# STM32H743 register map
File version: 2.4
CPU: CM7 r0p1, little endian, MPU, FPU, 4 interrupt priority bits
Registers are 32-bit, read-write, reset 0x0 unless marked. A register's access mark holds for its fields unless they carry their own. Offsets are from the block's base; [hi:lo] are bit positions; {n}, {i} and the like mark numbered series; 'fields as' and 'values as' point back to an identical list.

## RCC — 复位与时钟控制
Base 0x58024400
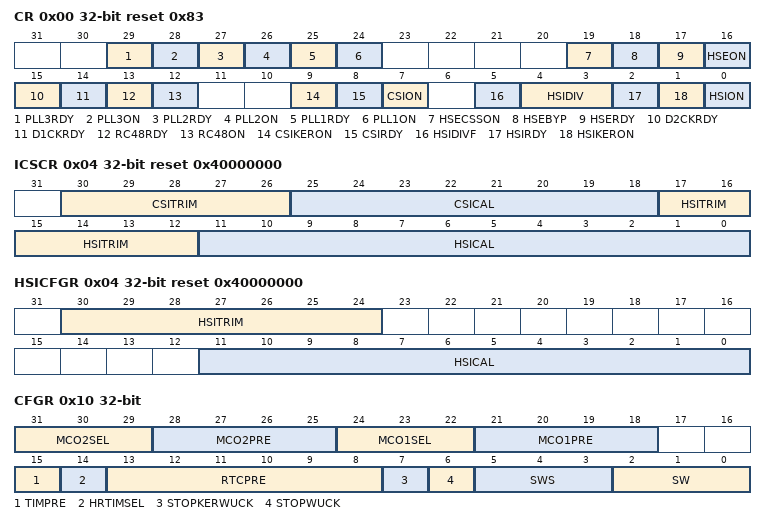
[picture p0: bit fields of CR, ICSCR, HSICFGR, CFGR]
0x00 CR reset 0x83 — 时钟控制寄存器
  [29] PLL3RDY — PLL3 时钟就绪标志位
  [28] PLL3ON — PLL3 使能
  [27] PLL2RDY — PLL2 时钟就绪标志位
  [26] PLL2ON — PLL2 使能
  [25] PLL1RDY — PLL1 时钟就绪标志位
  [24] PLL1ON — PLL1 使能
  [19] HSECSSON — HSE 时钟安全系统使能
  [18] HSEBYP — HSE 时钟旁路
  [17] HSERDY — HSE 时钟就绪标志位
  [16] HSEON — HSE 时钟使能
  [15] D2CKRDY — D2 域时钟就绪标志位
  [14] D1CKRDY — D1 域时钟就绪标志位
  [13] RC48RDY — RC48 时钟就绪标志位
  [12] RC48ON — RC48 时钟使能
  [9] CSIKERON — CSI 时钟停止模式下使能
  [8] CSIRDY — CSI 时钟就绪标志位
  [7] CSION — CSI 时钟使能
  [5] HSIDIVF — HSI 分频器标志位
  [4:3] HSIDIV — HSI 时钟分频器
  [2] HSIRDY — HSI 时钟就绪标志位
  [1] HSIKERON — 高速内部时钟停止模式下使能
  [0] HSION — 内部高速时钟使能
0x04 ICSCR access per field reset 0x40000000 — RCC 内部时钟源校准寄存器
  [30:26] CSITRIM rw — CSI 时钟微调
  [25:18] CSICAL ro — CSI 时钟校准值
  [17:12] HSITRIM rw — HSI 时钟微调
  [11:0] HSICAL ro — HSI 时钟校准值
0x04 HSICFGR access per field reset 0x40000000 (alternate view of ICSCR) — RCC HSI 配置寄存器
  [30:24] HSITRIM rw — HSI 时钟微调
  [11:0] HSICAL ro — HSI 时钟校准值
0x08 CRRCR ro — RCC 时钟恢复 RC 寄存器
  [9:0] RC48CAL — 内部 RC 48 MHz 时钟校准值
0x10 CFGR — RCC 时钟配置寄存器
  [31:29] MCO2SEL — 微控制器时钟输出 2
  [28:25] MCO2PRE — MCO2 预分频器
  [24:22] MCO1SEL — 微控制器时钟输出 1
  [21:18] MCO1PRE — MCO1 预分频器
  [15] TIMPRE — 定时器时钟预分频器选择
  [14] HRTIMSEL — 高分辨率定时器时钟预分频器选择
  [13:8] RTCPRE — RTC 时钟的 HSE 分频因子
  [7] STOPKERWUCK — 系统停止模式唤醒后内核时钟选择
  [6] STOPWUCK — 系统停止模式唤醒后系统时钟选择
  [5:3] SWS — 系统时钟切换状态
  [2:0] SW — 系统时钟切换
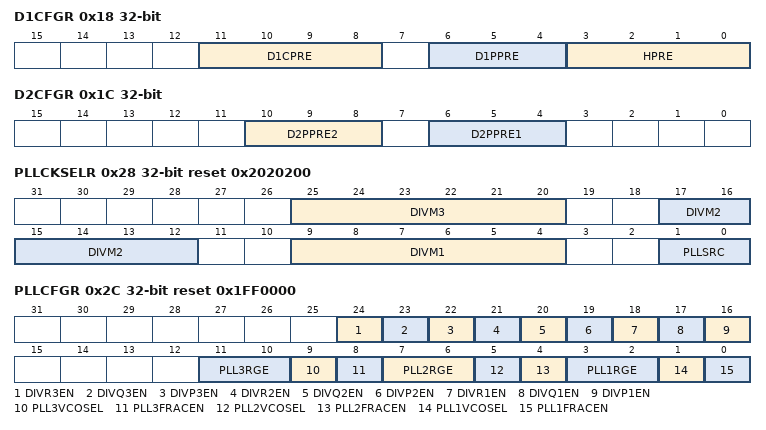
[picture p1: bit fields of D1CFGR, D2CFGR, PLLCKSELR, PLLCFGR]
0x18 D1CFGR — RCC 域 1 时钟配置寄存器
  [11:8] D1CPRE — D1 域内核预分频器
  [6:4] D1PPRE — D1 域 APB3 预分频器
  [3:0] HPRE — D1 域 AHB 预分频器
0x1C D2CFGR — RCC 域 2 时钟配置寄存器
  [10:8] D2PPRE2 — D2 域 APB2 预分频器
  [6:4] D2PPRE1 — D2 域 APB1 预分频器
0x20 D3CFGR — RCC 域 3 时钟配置寄存器
  [6:4] D3PPRE — D3 域 APB4 预分频器
0x28 PLLCKSELR reset 0x2020200 — RCC PLL 时钟源选择寄存器
  [25:20] DIVM3 — PLL3 预分频器
  [17:12] DIVM2 — PLL2 预分频器
  [9:4] DIVM1 — PLL1 预分频器
  [1:0] PLLSRC — DIVMx 与 PLL 时钟源选择
0x2C PLLCFGR reset 0x1FF0000 — RCC PLL 配置寄存器
  [24] DIVR3EN — PLL3 DIVR 分频器输出使能
  [23] DIVQ3EN — PLL3 DIVQ 分频器输出使能
  [22] DIVP3EN — PLL3 DIVP 分频器输出使能
  [21] DIVR2EN — PLL2 DIVR 分频器输出使能
  [20] DIVQ2EN — PLL2 DIVQ 分频器输出使能
  [19] DIVP2EN — PLL2 DIVP 分频器输出使能
  [18] DIVR1EN — PLL1 DIVR 分频器输出使能
  [17] DIVQ1EN — PLL1 DIVQ 分频器输出使能
  [16] DIVP1EN — PLL1 DIVP 分频器输出使能
  [11:10] PLL3RGE — PLL3 输入频率范围
  [9] PLL3VCOSEL — PLL3 VCO 选择
  [8] PLL3FRACEN — PLL3 小数锁存使能
  [7:6] PLL2RGE — PLL2 输入频率范围
  [5] PLL2VCOSEL — PLL2 VCO 选择
  [4] PLL2FRACEN — PLL2 小数锁存使能
  [3:2] PLL1RGE — PLL1 输入频率范围
  [1] PLL1VCOSEL — PLL1 VCO 选择
  [0] PLL1FRACEN — PLL1 小数锁存使能
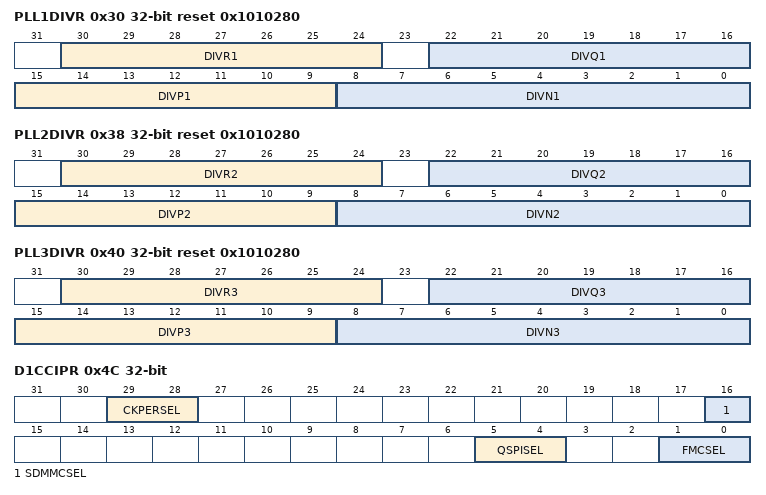
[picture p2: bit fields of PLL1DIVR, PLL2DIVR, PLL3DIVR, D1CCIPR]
0x30 PLL1DIVR reset 0x1010280 — RCC PLL1 分频器配置寄存器
  [30:24] DIVR1 — PLL2 DIVR 分频因子
  [22:16] DIVQ1 — PLL2 DIVQ 分频因子
  [15:9] DIVP1 — PLL2 DIVP 分频因子
  [8:0] DIVN1 — PLL2 VCO 倍频因子
{0x2C+8i} PLL{i}FRACR (i=1..3) — RCC PLL{i} 小数分频寄存器
  [15:3] FRACN{i} — PLL{i} VCO 倍频因子的小数部分
0x38 PLL2DIVR reset 0x1010280 — RCC PLL2 分频器配置寄存器
  [30:24] DIVR2 — PLL2 DIVR 分频因子
  [22:16] DIVQ2 — PLL2 DIVQ 分频因子
  [15:9] DIVP2 — PLL2 DIVP 分频因子
  [8:0] DIVN2 — PLL2 VCO 倍频因子
0x40 PLL3DIVR reset 0x1010280 — RCC PLL3 分频器配置寄存器
  [30:24] DIVR3 — PLL3 DIVR 分频因子
  [22:16] DIVQ3 — PLL3 DIVQ 分频因子
  [15:9] DIVP3 — PLL3 DIVP 分频因子
  [8:0] DIVN3 — PLL2 VCO 倍频因子
0x4C D1CCIPR — RCC 域 1 内核时钟配置寄存器
  [29:28] CKPERSEL — per_ck 时钟源选择
  [16] SDMMCSEL — SDMMC 内核时钟源选择
  [5:4] QSPISEL — QUADSPI 内核时钟源选择
  [1:0] FMCSEL — FMC 内核时钟源选择
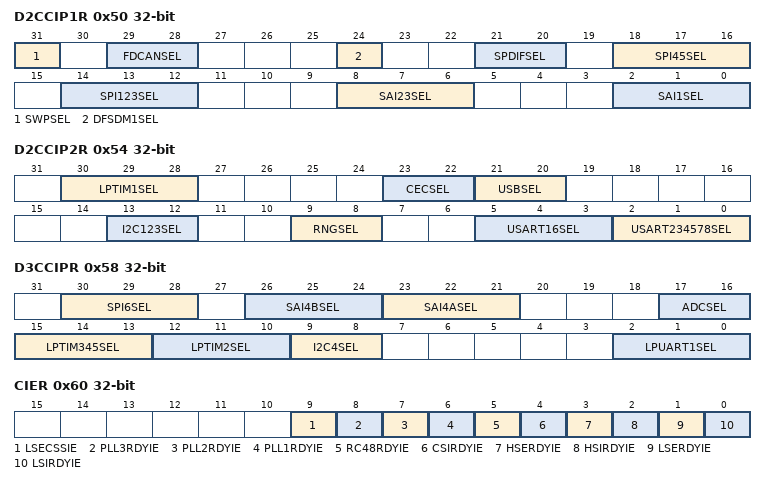
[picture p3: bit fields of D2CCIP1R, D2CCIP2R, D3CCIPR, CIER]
0x50 D2CCIP1R — RCC 域 2 内核时钟配置寄存器
  [31] SWPSEL — SWPMI 内核时钟源选择
  [29:28] FDCANSEL — FDCAN 内核时钟源选择
  [24] DFSDM1SEL — DFSDM1 内核 Clk 时钟源选择
  [21:20] SPDIFSEL — SPDIFRX 内核时钟源选择
  [18:16] SPI45SEL — SPI4 与 SPI5 内核时钟源选择
  [14:12] SPI123SEL — SPI/I2S1、2、3 内核时钟源选择
  [8:6] SAI23SEL — SAI2 与 SAI3 内核时钟源选择
  [2:0] SAI1SEL — SAI1 与 DFSDM1 内核 Aclk 时钟源选择
0x54 D2CCIP2R — RCC 域 2 内核时钟配置寄存器
  [30:28] LPTIM1SEL — LPTIM1 内核时钟源选择
  [23:22] CECSEL — HDMI-CEC 内核时钟源选择
  [21:20] USBSEL — USBOTG 1 与 USBOTG 2 内核时钟源选择
  [13:12] I2C123SEL — I2C1、2、3 内核时钟源选择
  [9:8] RNGSEL — RNG 内核时钟源选择
  [5:3] USART16SEL — USART1 与 USART6 内核时钟源选择
  [2:0] USART234578SEL — USART2/3、UART4/5、7/8（APB1）内核时钟源选择
0x58 D3CCIPR — RCC 域 3 内核时钟配置寄存器
  [30:28] SPI6SEL — SPI6 内核时钟源选择
  [26:24] SAI4BSEL — SAI4 子模块 B 内核时钟源选择
  [23:21] SAI4ASEL — SAI4 子模块 A 内核时钟源选择
  [17:16] ADCSEL — SAR ADC 内核时钟源选择
  [15:13] LPTIM345SEL — LPTIM3、4、5 内核时钟源选择
  [12:10] LPTIM2SEL — LPTIM2 内核时钟源选择
  [9:8] I2C4SEL — I2C4 内核时钟源选择
  [2:0] LPUART1SEL — LPUART1 内核时钟源选择
0x60 CIER — RCC 时钟源中断使能寄存器
  [9] LSECSSIE — LSE 时钟安全系统中断使能
  [8] PLL3RDYIE — PLL3 就绪中断使能
  [7] PLL2RDYIE — PLL2 就绪中断使能
  [6] PLL1RDYIE — PLL1 就绪中断使能
  [5] RC48RDYIE — RC48 就绪中断使能
  [4] CSIRDYIE — CSI 就绪中断使能
  [3] HSERDYIE — HSE 就绪中断使能
  [2] HSIRDYIE — HSI 就绪中断使能
  [1] LSERDYIE — LSE 就绪中断使能
  [0] LSIRDYIE — LSI 就绪中断使能
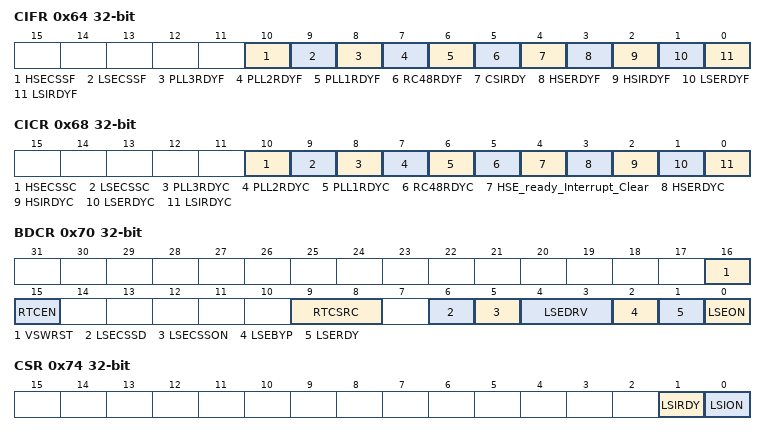
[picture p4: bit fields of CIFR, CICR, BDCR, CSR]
0x64 CIFR — RCC 时钟源中断标志寄存器
  [10] HSECSSF — HSE 时钟安全系统中断标志位
  [9] LSECSSF — LSE 时钟安全系统中断标志位
  [8] PLL3RDYF — PLL3 就绪中断标志位
  [7] PLL2RDYF — PLL2 就绪中断标志位
  [6] PLL1RDYF — PLL1 就绪中断标志位
  [5] RC48RDYF — RC48 就绪中断标志位
  [4] CSIRDY — CSI 就绪中断标志位
  [3] HSERDYF — HSE 就绪中断标志位
  [2] HSIRDYF — HSI 就绪中断标志位
  [1] LSERDYF — LSE 就绪中断标志位
  [0] LSIRDYF — LSI 就绪中断标志位
0x68 CICR — RCC 时钟源中断清除寄存器
  [10] HSECSSC — HSE 时钟安全系统中断清除
  [9] LSECSSC — LSE 时钟安全系统中断清除
  [8] PLL3RDYC — PLL3 就绪中断清除
  [7] PLL2RDYC — PLL2 就绪中断清除
  [6] PLL1RDYC — PLL1 就绪中断清除
  [5] RC48RDYC — RC48 就绪中断清除
  [4] HSE_ready_Interrupt_Clear — CSI 就绪中断清除
  [3] HSERDYC — HSE 就绪中断清除
  [2] HSIRDYC — HSI 就绪中断清除
  [1] LSERDYC — LSE 就绪中断清除
  [0] LSIRDYC — LSI 就绪中断清除
0x70 BDCR — RCC 备份域控制寄存器
  [16] VSWRST — VSwitch 域软件复位
  [15] RTCEN — RTC 时钟使能
  [9:8] RTCSRC — RTC 时钟源选择
  [6] LSECSSD — LSE 时钟安全系统故障检测
  [5] LSECSSON — LSE 时钟安全系统使能
  [4:3] LSEDRV — LSE 振荡器驱动能力
  [2] LSEBYP — LSE 振荡器旁路
  [1] LSERDY — LSE 振荡器就绪
  [0] LSEON — LSE 振荡器使能
0x74 CSR — RCC 时钟控制与状态寄存器
  [1] LSIRDY — LSI 振荡器就绪
  [0] LSION — LSI 振荡器使能
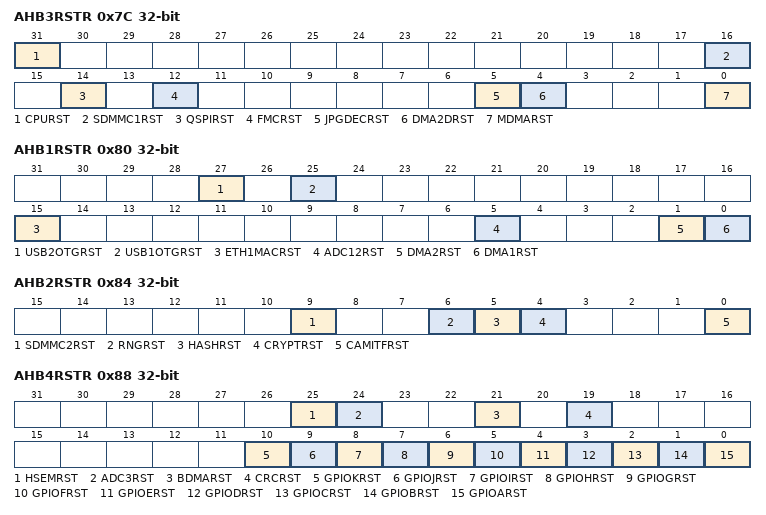
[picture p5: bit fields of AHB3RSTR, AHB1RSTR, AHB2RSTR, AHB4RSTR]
0x7C AHB3RSTR — RCC AHB3 复位寄存器
  [31] CPURST — CPU 复位
  [16] SDMMC1RST — SDMMC1 及 SDMMC1 延迟模块复位
  [14] QSPIRST — QUADSPI 及 QUADSPI 延迟模块复位
  [12] FMCRST — FMC 模块复位
  [5] JPGDECRST — JPGDEC 模块复位
  [4] DMA2DRST — DMA2D 模块复位
  [0] MDMARST — MDMA 模块复位
0x80 AHB1RSTR — RCC AHB1 外设复位寄存器
  [27] USB2OTGRST — USB2OTG 模块复位
  [25] USB1OTGRST — USB1OTG 模块复位
  [15] ETH1MACRST — ETH1MAC 模块复位
  [5] ADC12RST — ADC1/2 模块复位
  [1] DMA2RST — DMA2 模块复位
  [0] DMA1RST — DMA1 模块复位
0x84 AHB2RSTR — RCC AHB2 外设复位寄存器
  [9] SDMMC2RST — SDMMC2 及 SDMMC2 延迟模块复位
  [6] RNGRST — 随机数生成器模块复位
  [5] HASHRST — 哈希模块复位
  [4] CRYPTRST — 加密模块复位
  [0] CAMITFRST — CAMITF 模块复位
0x88 AHB4RSTR — RCC AHB4 外设复位寄存器
  [25] HSEMRST — HSEM 模块复位
  [24] ADC3RST — ADC3 模块复位
  [21] BDMARST — BDMA 模块复位
  [19] CRCRST — CRC 模块复位
  [10] GPIOKRST — GPIO 模块复位
  [9] GPIOJRST — GPIO 模块复位
  [8] GPIOIRST — GPIO 模块复位
  [7] GPIOHRST — GPIO 模块复位
  [6] GPIOGRST — GPIO 模块复位
  [5] GPIOFRST — GPIO 模块复位
  [4] GPIOERST — GPIO 模块复位
  [3] GPIODRST — GPIO 模块复位
  [2] GPIOCRST — GPIO 模块复位
  [1] GPIOBRST — GPIO 模块复位
  [0] GPIOARST — GPIO 模块复位
0x8C APB3RSTR — RCC APB3 外设复位寄存器
  [3] LTDCRST — LTDC 模块复位
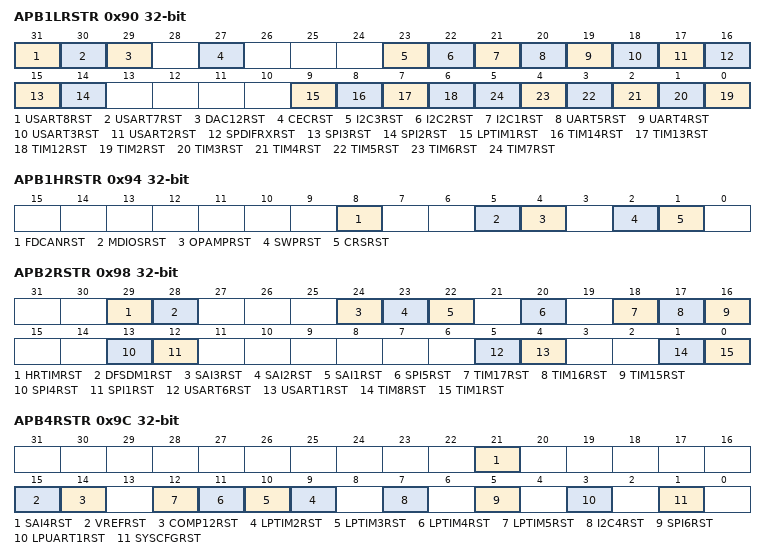
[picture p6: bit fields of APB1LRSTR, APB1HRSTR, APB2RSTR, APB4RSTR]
0x90 APB1LRSTR — RCC APB1 外设复位寄存器
  [31] USART8RST — USART8 模块复位
  [30] USART7RST — USART7 模块复位
  [29] DAC12RST — DAC1/2 模块复位
  [27] CECRST — HDMI-CEC 模块复位
  [23] I2C3RST — I2C3 模块复位
  [22] I2C2RST — I2C2 模块复位
  [21] I2C1RST — I2C1 模块复位
  [20] UART5RST — UART5 模块复位
  [19] UART4RST — UART4 模块复位
  [18] USART3RST — USART3 模块复位
  [17] USART2RST — USART2 模块复位
  [16] SPDIFRXRST — SPDIFRX 模块复位
  [15] SPI3RST — SPI3 模块复位
  [14] SPI2RST — SPI2 模块复位
  [9] LPTIM1RST — TIM 模块复位
  [8] TIM14RST — TIM 模块复位
  [7] TIM13RST — TIM 模块复位
  [6] TIM12RST — TIM 模块复位
  [n-2] TIM{n}RST (n=2..7) — TIM 模块复位
0x94 APB1HRSTR — RCC APB1 外设复位寄存器
  [8] FDCANRST — FDCAN 模块复位
  [5] MDIOSRST — MDIOS 模块复位
  [4] OPAMPRST — OPAMP 模块复位
  [2] SWPRST — SWPMI 模块复位
  [1] CRSRST — 时钟恢复系统复位
0x98 APB2RSTR — RCC APB2 外设复位寄存器
  [29] HRTIMRST — HRTIM 模块复位
  [28] DFSDM1RST — DFSDM1 模块复位
  [24] SAI3RST — SAI3 模块复位
  [23] SAI2RST — SAI2 模块复位
  [22] SAI1RST — SAI1 模块复位
  [20] SPI5RST — SPI5 模块复位
  [18] TIM17RST — TIM17 模块复位
  [17] TIM16RST — TIM16 模块复位
  [16] TIM15RST — TIM15 模块复位
  [13] SPI4RST — SPI4 模块复位
  [12] SPI1RST — SPI1 模块复位
  [5] USART6RST — USART6 模块复位
  [4] USART1RST — USART1 模块复位
  [1] TIM8RST — TIM8 模块复位
  [0] TIM1RST — TIM1 模块复位
0x9C APB4RSTR — RCC APB4 外设复位寄存器
  [21] SAI4RST — SAI4 模块复位
  [15] VREFRST — VREF 模块复位
  [14] COMP12RST — COMP12 模块复位
  [n+7] LPTIM{n}RST (n=2..5) — LPTIM{n} 模块复位
  [7] I2C4RST — I2C4 模块复位
  [5] SPI6RST — SPI6 模块复位
  [3] LPUART1RST — LPUART1 模块复位
  [1] SYSCFGRST — SYSCFG 模块复位
0xA0 GCR — RCC 全局控制寄存器
  [0] WW1RSC — WWDG1 复位范围控制
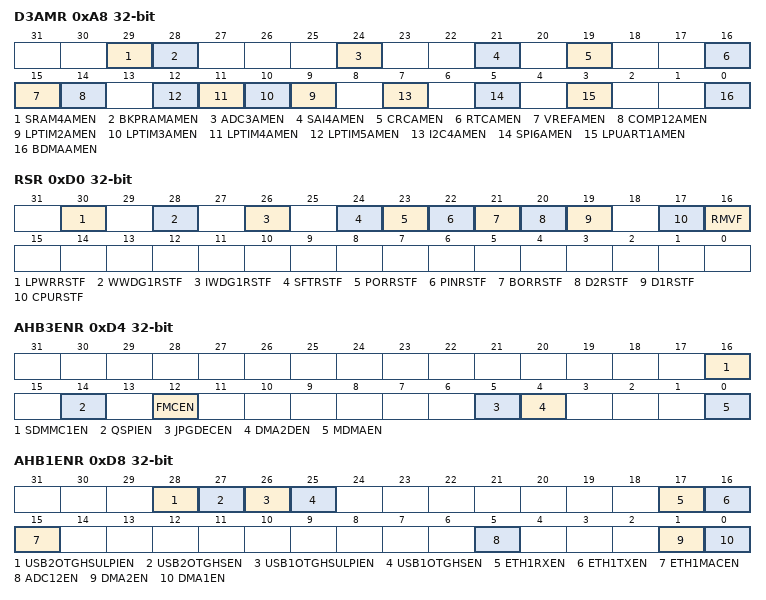
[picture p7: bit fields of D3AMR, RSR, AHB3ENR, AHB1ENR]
0xA8 D3AMR — RCC D3 自主模式寄存器
  [29] SRAM4AMEN — SRAM4 自主模式使能
  [28] BKPRAMAMEN — 备份 RAM 自主模式使能
  [24] ADC3AMEN — ADC3 自主模式使能
  [21] SAI4AMEN — SAI4 自主模式使能
  [19] CRCAMEN — CRC 自主模式使能
  [16] RTCAMEN — RTC 自主模式使能
  [15] VREFAMEN — VREF 自主模式使能
  [14] COMP12AMEN — COMP12 自主模式使能
  [n+7] LPTIM{n}AMEN (n=2..5) — LPTIM{n} 自主模式使能
  [7] I2C4AMEN — I2C4 自主模式使能
  [5] SPI6AMEN — SPI6 自主模式使能
  [3] LPUART1AMEN — LPUART1 自主模式使能
  [0] BDMAAMEN — BDMA 与 DMAMUX 自主模式使能
0xD0 RSR — RCC 复位状态寄存器
  [30] LPWRRSTF — D1 DStandby 或 CPU CStop 非法操作导致复位标志位
  [28] WWDG1RSTF — 窗口看门狗复位标志位
  [26] IWDG1RSTF — 独立看门狗复位标志位
  [24] SFTRSTF — 来自 CPU 复位的系统复位标志位
  [23] PORRSTF — POR/PDR 复位标志位
  [22] PINRSTF — 引脚复位标志位（NRST）
  [21] BORRSTF — BOR 复位标志位
  [20] D2RSTF — D2 域电源开关复位标志位
  [19] D1RSTF — D1 域电源开关复位标志位
  [17] CPURSTF — CPU 复位标志位
  [16] RMVF — 清除复位标志位
0xD4 AHB3ENR — RCC AHB3 时钟寄存器
  [16] SDMMC1EN — SDMMC1 及 SDMMC1 延迟时钟使能
  [14] QSPIEN — QUADSPI 及 QUADSPI 延迟时钟使能
  [12] FMCEN — FMC 外设时钟使能
  [5] JPGDECEN — JPGDEC 外设时钟使能
  [4] DMA2DEN — DMA2D 外设时钟使能
  [0] MDMAEN — MDMA 外设时钟使能
0xD8 AHB1ENR — RCC AHB1 时钟寄存器
  [28] USB2OTGHSULPIEN — USB_PHY2 时钟使能
  [27] USB2OTGHSEN — USB2OTG 外设时钟使能
  [26] USB1OTGHSULPIEN — USB_PHY1 时钟使能
  [25] USB1OTGHSEN — USB1OTG（OTG_HS1）外设时钟使能
  [17] ETH1RXEN — 以太网接收时钟使能
  [16] ETH1TXEN — 以太网发送时钟使能
  [15] ETH1MACEN — 以太网 MAC 总线接口时钟使能
  [5] ADC12EN — ADC1/2 外设时钟使能
  [1] DMA2EN — DMA2 时钟使能
  [0] DMA1EN — DMA1 时钟使能
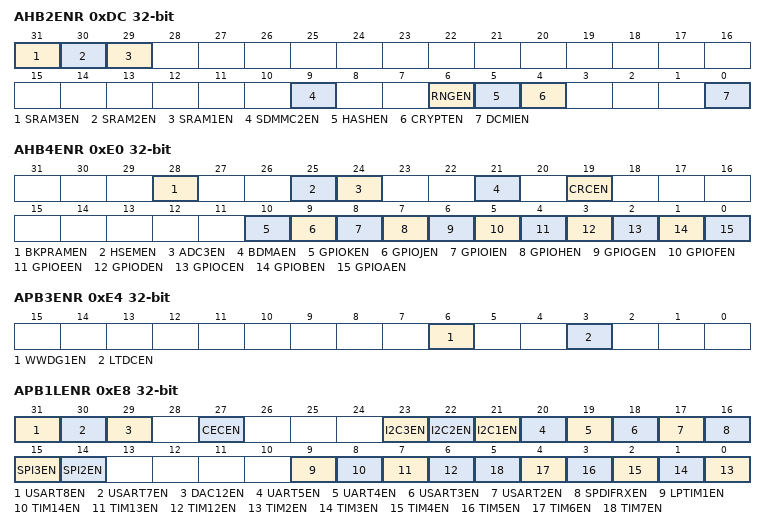
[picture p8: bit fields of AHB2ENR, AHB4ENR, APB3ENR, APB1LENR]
0xDC AHB2ENR — RCC AHB2 时钟寄存器
  [31] SRAM3EN — SRAM3 模块使能
  [30] SRAM2EN — SRAM2 模块使能
  [29] SRAM1EN — SRAM1 模块使能
  [9] SDMMC2EN — SDMMC2 及 SDMMC2 延迟时钟使能
  [6] RNGEN — RNG 外设时钟使能
  [5] HASHEN — HASH 外设时钟使能
  [4] CRYPTEN — CRYPT 外设时钟使能
  [0] DCMIEN — DCMI 外设时钟使能
0xE0 AHB4ENR — RCC AHB4 时钟寄存器
  [28] BKPRAMEN — 备份 RAM 时钟使能
  [25] HSEMEN — HSEM 外设时钟使能
  [24] ADC3EN — ADC3 外设时钟使能
  [21] BDMAEN — BDMA 与 DMAMUX2 时钟使能
  [19] CRCEN — CRC 外设时钟使能
  [10] GPIOKEN — GPIO 外设时钟使能
  [9] GPIOJEN — GPIO 外设时钟使能
  [8] GPIOIEN — GPIO 外设时钟使能
  [7] GPIOHEN — GPIO 外设时钟使能
  [6] GPIOGEN — GPIO 外设时钟使能
  [5] GPIOFEN — GPIO 外设时钟使能
  [4] GPIOEEN — GPIO 外设时钟使能
  [3] GPIODEN — GPIO 外设时钟使能
  [2] GPIOCEN — GPIO 外设时钟使能
  [1] GPIOBEN — GPIO 外设时钟使能
  [0] GPIOAEN — GPIO 外设时钟使能
0xE4 APB3ENR — RCC APB3 时钟寄存器
  [6] WWDG1EN — WWDG1 时钟使能
  [3] LTDCEN — LTDC 外设时钟使能
0xE8 APB1LENR — RCC APB1 时钟寄存器
  [31] USART8EN — USART8 外设时钟使能
  [30] USART7EN — USART7 外设时钟使能
  [29] DAC12EN — DAC1/2 外设时钟使能
  [27] CECEN — HDMI-CEC 外设时钟使能
  [23] I2C3EN — I2C3 外设时钟使能
  [22] I2C2EN — I2C2 外设时钟使能
  [21] I2C1EN — I2C1 外设时钟使能
  [20] UART5EN — UART5 外设时钟使能
  [19] UART4EN — UART4 外设时钟使能
  [18] USART3EN — USART3 外设时钟使能
  [17] USART2EN — USART2 外设时钟使能
  [16] SPDIFRXEN — SPDIFRX 外设时钟使能
  [15] SPI3EN — SPI3 外设时钟使能
  [14] SPI2EN — SPI2 外设时钟使能
  [9] LPTIM1EN — LPTIM1 外设时钟使能
  [8] TIM14EN — TIM 外设时钟使能
  [7] TIM13EN — TIM 外设时钟使能
  [6] TIM12EN — TIM 外设时钟使能
  [n-2] TIM{n}EN (n=2..7) — TIM 外设时钟使能
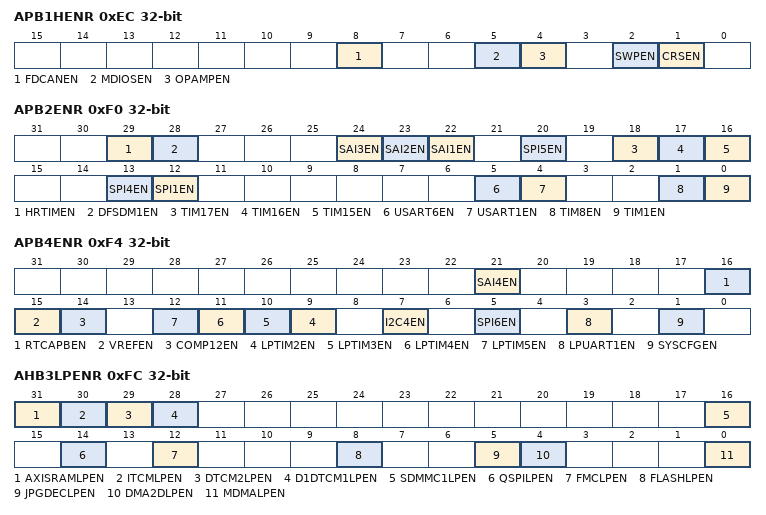
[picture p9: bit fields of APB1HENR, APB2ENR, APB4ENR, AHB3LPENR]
0xEC APB1HENR — RCC APB1 时钟寄存器
  [8] FDCANEN — FDCAN 外设时钟使能
  [5] MDIOSEN — MDIOS 外设时钟使能
  [4] OPAMPEN — OPAMP 外设时钟使能
  [2] SWPEN — SWPMI 外设时钟使能
  [1] CRSEN — 时钟恢复系统外设时钟使能
0xF0 APB2ENR — RCC APB2 时钟寄存器
  [29] HRTIMEN — HRTIM 外设时钟使能
  [28] DFSDM1EN — DFSDM1 外设时钟使能
  [24] SAI3EN — SAI3 外设时钟使能
  [23] SAI2EN — SAI2 外设时钟使能
  [22] SAI1EN — SAI1 外设时钟使能
  [20] SPI5EN — SPI5 外设时钟使能
  [18] TIM17EN — TIM17 外设时钟使能
  [17] TIM16EN — TIM16 外设时钟使能
  [16] TIM15EN — TIM15 外设时钟使能
  [13] SPI4EN — SPI4 外设时钟使能
  [12] SPI1EN — SPI1 外设时钟使能
  [5] USART6EN — USART6 外设时钟使能
  [4] USART1EN — USART1 外设时钟使能
  [1] TIM8EN — TIM8 外设时钟使能
  [0] TIM1EN — TIM1 外设时钟使能
0xF4 APB4ENR — RCC APB4 时钟寄存器
  [21] SAI4EN — SAI4 外设时钟使能
  [16] RTCAPBEN — RTC APB 时钟使能
  [15] VREFEN — VREF 外设时钟使能
  [14] COMP12EN — COMP1/2 外设时钟使能
  [n+7] LPTIM{n}EN (n=2..5) — LPTIM{n} 外设时钟使能
  [7] I2C4EN — I2C4 外设时钟使能
  [5] SPI6EN — SPI6 外设时钟使能
  [3] LPUART1EN — LPUART1 外设时钟使能
  [1] SYSCFGEN — SYSCFG 外设时钟使能
0xFC AHB3LPENR — RCC AHB3 睡眠时钟寄存器
  [31] AXISRAMLPEN — CSleep 模式下 AXISRAM 模块时钟使能
  [30] ITCMLPEN — CSleep 模式下 D1 ITCM 模块时钟使能
  [29] DTCM2LPEN — CSleep 模式下 D1 DTCM2 模块时钟使能
  [28] D1DTCM1LPEN — CSleep 模式下 D1 DTCM1 模块时钟使能
  [16] SDMMC1LPEN — CSleep 模式下 SDMMC1 及 SDMMC1 延迟时钟使能
  [14] QSPILPEN — CSleep 模式下 QUADSPI 及 QUADSPI 延迟时钟使能
  [12] FMCLPEN — CSleep 模式下 FMC 外设时钟使能
  [8] FLASHLPEN — CSleep 模式下 FLITF 时钟使能
  [5] JPGDECLPEN — CSleep 模式下 JPGDEC 时钟使能
  [4] DMA2DLPEN — CSleep 模式下 DMA2D 时钟使能
  [0] MDMALPEN — CSleep 模式下 MDMA 时钟使能
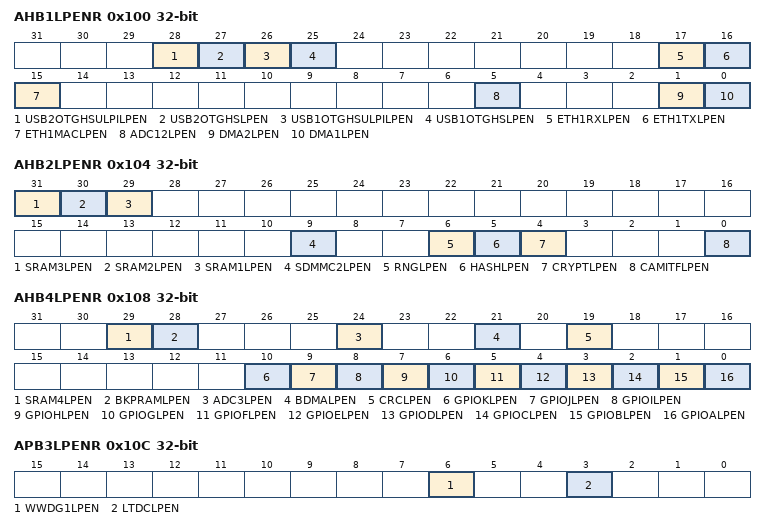
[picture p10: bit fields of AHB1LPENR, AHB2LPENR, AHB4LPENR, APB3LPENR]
0x100 AHB1LPENR — RCC AHB1 睡眠时钟寄存器
  [28] USB2OTGHSULPILPEN — CSleep 模式下 USB_PHY2 时钟使能
  [27] USB2OTGHSLPEN — CSleep 模式下 USB2OTG 外设时钟使能
  [26] USB1OTGHSULPILPEN — CSleep 模式下 USB_PHY1 时钟使能
  [25] USB1OTGHSLPEN — CSleep 模式下 USB1OTG 外设时钟使能
  [17] ETH1RXLPEN — CSleep 模式下以太网接收时钟使能
  [16] ETH1TXLPEN — CSleep 模式下以太网发送时钟使能
  [15] ETH1MACLPEN — CSleep 模式下以太网 MAC 总线接口时钟使能
  [5] ADC12LPEN — CSleep 模式下 ADC1/2 外设时钟使能
  [1] DMA2LPEN — CSleep 模式下 DMA2 时钟使能
  [0] DMA1LPEN — CSleep 模式下 DMA1 时钟使能
0x104 AHB2LPENR — RCC AHB2 睡眠时钟寄存器
  [31] SRAM3LPEN — CSleep 模式下 SRAM3 时钟使能
  [30] SRAM2LPEN — CSleep 模式下 SRAM2 时钟使能
  [29] SRAM1LPEN — CSleep 模式下 SRAM1 时钟使能
  [9] SDMMC2LPEN — CSleep 模式下 SDMMC2 及 SDMMC2 延迟时钟使能
  [6] RNGLPEN — CSleep 模式下 RNG 外设时钟使能
  [5] HASHLPEN — CSleep 模式下 HASH 外设时钟使能
  [4] CRYPTLPEN — CSleep 模式下 CRYPT 外设时钟使能
  [0] CAMITFLPEN — CSleep 模式下 CAMITF 外设时钟使能
0x108 AHB4LPENR — RCC AHB4 睡眠时钟寄存器
  [29] SRAM4LPEN — CSleep 模式下 SRAM4 时钟使能
  [28] BKPRAMLPEN — CSleep 模式下备份 RAM 时钟使能
  [24] ADC3LPEN — CSleep 模式下 ADC3 外设时钟使能
  [21] BDMALPEN — CSleep 模式下 BDMA 时钟使能
  [19] CRCLPEN — CSleep 模式下 CRC 外设时钟使能
  [10] GPIOKLPEN — CSleep 模式下 GPIO 外设时钟使能
  [9] GPIOJLPEN — CSleep 模式下 GPIO 外设时钟使能
  [8] GPIOILPEN — CSleep 模式下 GPIO 外设时钟使能
  [7] GPIOHLPEN — CSleep 模式下 GPIO 外设时钟使能
  [6] GPIOGLPEN — CSleep 模式下 GPIO 外设时钟使能
  [5] GPIOFLPEN — CSleep 模式下 GPIO 外设时钟使能
  [4] GPIOELPEN — CSleep 模式下 GPIO 外设时钟使能
  [3] GPIODLPEN — CSleep 模式下 GPIO 外设时钟使能
  [2] GPIOCLPEN — CSleep 模式下 GPIO 外设时钟使能
  [1] GPIOBLPEN — CSleep 模式下 GPIO 外设时钟使能
  [0] GPIOALPEN — CSleep 模式下 GPIO 外设时钟使能
0x10C APB3LPENR — RCC APB3 睡眠时钟寄存器
  [6] WWDG1LPEN — CSleep 模式下 WWDG1 时钟使能
  [3] LTDCLPEN — CSleep 模式下 LTDC 外设时钟使能
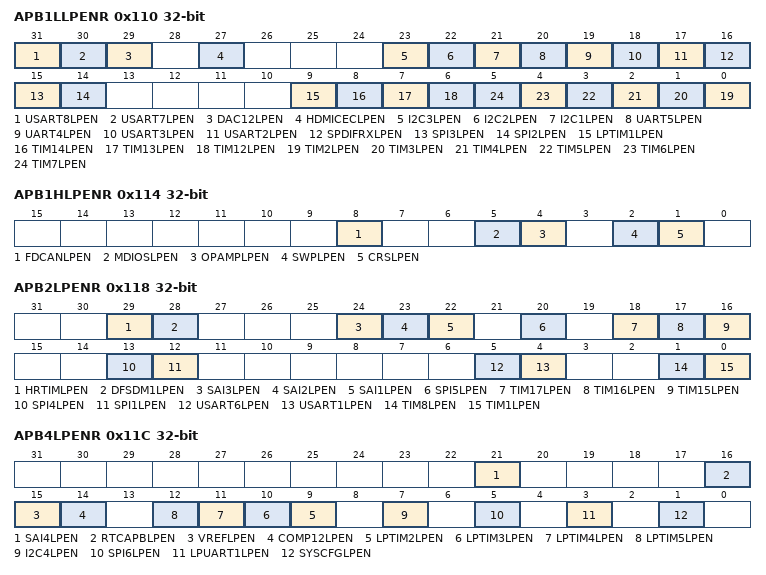
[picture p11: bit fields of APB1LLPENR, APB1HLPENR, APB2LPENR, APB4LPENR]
0x110 APB1LLPENR — RCC APB1 低睡眠时钟寄存器
  [31] USART8LPEN — CSleep 模式下 USART8 外设时钟使能
  [30] USART7LPEN — CSleep 模式下 USART7 外设时钟使能
  [29] DAC12LPEN — CSleep 模式下 DAC1/2 外设时钟使能
  [27] HDMICECLPEN — CSleep 模式下 HDMI-CEC 外设时钟使能
  [23] I2C3LPEN — CSleep 模式下 I2C3 外设时钟使能
  [22] I2C2LPEN — CSleep 模式下 I2C2 外设时钟使能
  [21] I2C1LPEN — CSleep 模式下 I2C1 外设时钟使能
  [20] UART5LPEN — CSleep 模式下 UART5 外设时钟使能
  [19] UART4LPEN — CSleep 模式下 UART4 外设时钟使能
  [18] USART3LPEN — CSleep 模式下 USART3 外设时钟使能
  [17] USART2LPEN — CSleep 模式下 USART2 外设时钟使能
  [16] SPDIFRXLPEN — CSleep 模式下 SPDIFRX 外设时钟使能
  [15] SPI3LPEN — CSleep 模式下 SPI3 外设时钟使能
  [14] SPI2LPEN — CSleep 模式下 SPI2 外设时钟使能
  [9] LPTIM1LPEN — CSleep 模式下 LPTIM1 外设时钟使能
  [8] TIM14LPEN — CSleep 模式下 TIM14 外设时钟使能
  [7] TIM13LPEN — CSleep 模式下 TIM13 外设时钟使能
  [6] TIM12LPEN — CSleep 模式下 TIM12 外设时钟使能
  [n-2] TIM{n}LPEN (n=2..7) — CSleep 模式下 TIM{n} 外设时钟使能
0x114 APB1HLPENR — RCC APB1 高睡眠时钟寄存器
  [8] FDCANLPEN — CSleep 模式下 FDCAN 外设时钟使能
  [5] MDIOSLPEN — CSleep 模式下 MDIOS 外设时钟使能
  [4] OPAMPLPEN — CSleep 模式下 OPAMP 外设时钟使能
  [2] SWPLPEN — CSleep 模式下 SWPMI 外设时钟使能
  [1] CRSLPEN — CSleep 模式下时钟恢复系统外设时钟使能
0x118 APB2LPENR — RCC APB2 睡眠时钟寄存器
  [29] HRTIMLPEN — CSleep 模式下 HRTIM 外设时钟使能
  [28] DFSDM1LPEN — CSleep 模式下 DFSDM1 外设时钟使能
  [24] SAI3LPEN — CSleep 模式下 SAI3 外设时钟使能
  [23] SAI2LPEN — CSleep 模式下 SAI2 外设时钟使能
  [22] SAI1LPEN — CSleep 模式下 SAI1 外设时钟使能
  [20] SPI5LPEN — CSleep 模式下 SPI5 外设时钟使能
  [18] TIM17LPEN — CSleep 模式下 TIM17 外设时钟使能
  [17] TIM16LPEN — CSleep 模式下 TIM16 外设时钟使能
  [16] TIM15LPEN — CSleep 模式下 TIM15 外设时钟使能
  [13] SPI4LPEN — CSleep 模式下 SPI4 外设时钟使能
  [12] SPI1LPEN — CSleep 模式下 SPI1 外设时钟使能
  [5] USART6LPEN — CSleep 模式下 USART6 外设时钟使能
  [4] USART1LPEN — CSleep 模式下 USART1 外设时钟使能
  [1] TIM8LPEN — CSleep 模式下 TIM8 外设时钟使能
  [0] TIM1LPEN — CSleep 模式下 TIM1 外设时钟使能
0x11C APB4LPENR — RCC APB4 睡眠时钟寄存器
  [21] SAI4LPEN — CSleep 模式下 SAI4 外设时钟使能
  [16] RTCAPBLPEN — CSleep 模式下 RTC APB 时钟使能
  [15] VREFLPEN — CSleep 模式下 VREF 外设时钟使能
  [14] COMP12LPEN — CSleep 模式下 COMP1/2 外设时钟使能
  [n+7] LPTIM{n}LPEN (n=2..5) — CSleep 模式下 LPTIM{n} 外设时钟使能
  [7] I2C4LPEN — CSleep 模式下 I2C4 外设时钟使能
  [5] SPI6LPEN — CSleep 模式下 SPI6 外设时钟使能
  [3] LPUART1LPEN — CSleep 模式下 LPUART1 外设时钟使能
  [1] SYSCFGLPEN — CSleep 模式下 SYSCFG 外设时钟使能
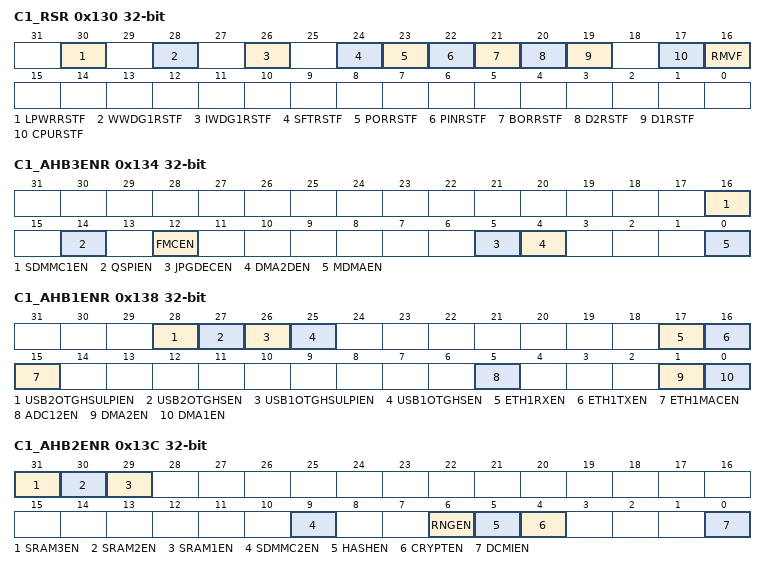
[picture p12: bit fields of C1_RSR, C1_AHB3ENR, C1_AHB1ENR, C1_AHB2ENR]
0x130 C1_RSR — RCC 复位状态寄存器
  fields as RSR
0x134 C1_AHB3ENR — RCC AHB3 时钟寄存器
  fields as AHB3ENR
0x138 C1_AHB1ENR — RCC AHB1 时钟寄存器
  fields as AHB1ENR
0x13C C1_AHB2ENR — RCC AHB2 时钟寄存器
  fields as AHB2ENR
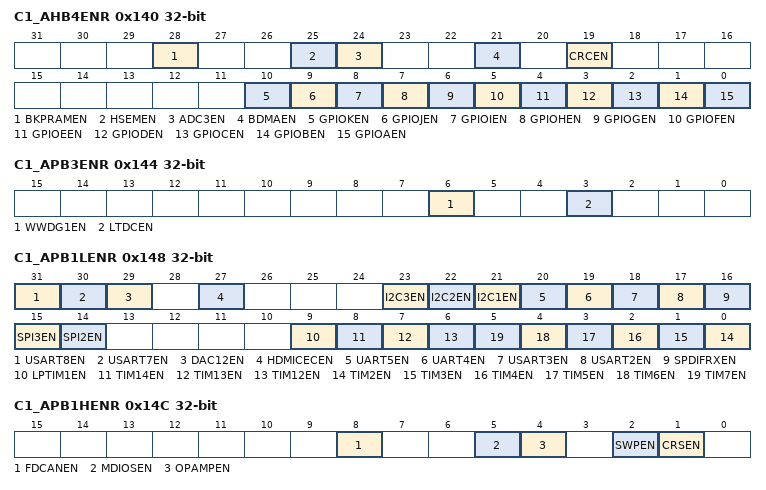
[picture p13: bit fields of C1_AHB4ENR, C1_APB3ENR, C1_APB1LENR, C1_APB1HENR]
0x140 C1_AHB4ENR — RCC AHB4 时钟寄存器
  fields as AHB4ENR
0x144 C1_APB3ENR — RCC APB3 时钟寄存器
  [6] WWDG1EN — WWDG1 时钟使能
  [3] LTDCEN — LTDC 外设时钟使能
0x148 C1_APB1LENR — RCC APB1 时钟寄存器
  [31] USART8EN — USART8 外设时钟使能
  [30] USART7EN — USART7 外设时钟使能
  [29] DAC12EN — DAC1/2 外设时钟使能
  [27] HDMICECEN — HDMI-CEC 外设时钟使能
  [23] I2C3EN — I2C3 外设时钟使能
  [22] I2C2EN — I2C2 外设时钟使能
  [21] I2C1EN — I2C1 外设时钟使能
  [20] UART5EN — UART5 外设时钟使能
  [19] UART4EN — UART4 外设时钟使能
  [18] USART3EN — USART3 外设时钟使能
  [17] USART2EN — USART2 外设时钟使能
  [16] SPDIFRXEN — SPDIFRX 外设时钟使能
  [15] SPI3EN — SPI3 外设时钟使能
  [14] SPI2EN — SPI2 外设时钟使能
  [9] LPTIM1EN — LPTIM1 外设时钟使能
  [8] TIM14EN — TIM 外设时钟使能
  [7] TIM13EN — TIM 外设时钟使能
  [6] TIM12EN — TIM 外设时钟使能
  [n-2] TIM{n}EN (n=2..7) — TIM 外设时钟使能
0x14C C1_APB1HENR — RCC APB1 时钟寄存器
  fields as APB1HENR
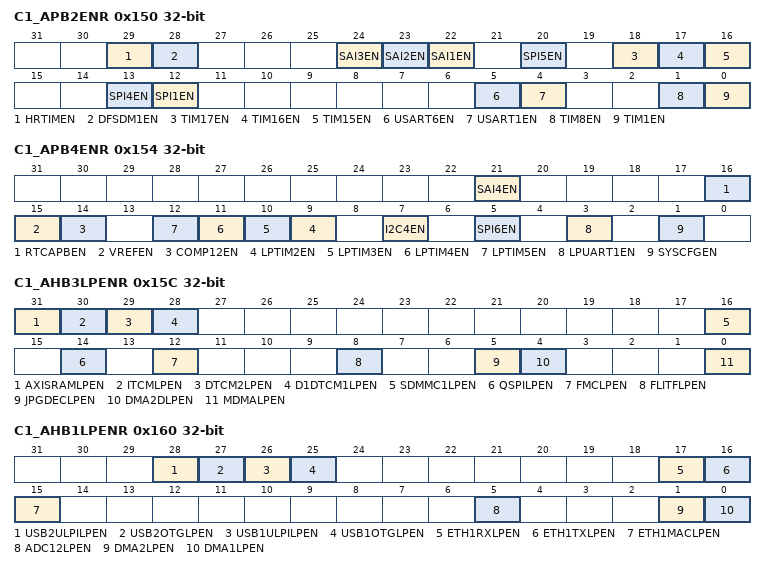
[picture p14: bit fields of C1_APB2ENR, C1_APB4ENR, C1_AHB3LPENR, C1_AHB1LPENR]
0x150 C1_APB2ENR — RCC APB2 时钟寄存器
  fields as APB2ENR
0x154 C1_APB4ENR — RCC APB4 时钟寄存器
  fields as APB4ENR
0x15C C1_AHB3LPENR — RCC AHB3 睡眠时钟寄存器
  [31] AXISRAMLPEN — CSleep 模式下 AXISRAM 模块时钟使能
  [30] ITCMLPEN — CSleep 模式下 D1 ITCM 模块时钟使能
  [29] DTCM2LPEN — CSleep 模式下 D1 DTCM2 模块时钟使能
  [28] D1DTCM1LPEN — CSleep 模式下 D1 DTCM1 模块时钟使能
  [16] SDMMC1LPEN — CSleep 模式下 SDMMC1 及 SDMMC1 延迟时钟使能
  [14] QSPILPEN — CSleep 模式下 QUADSPI 及 QUADSPI 延迟时钟使能
  [12] FMCLPEN — CSleep 模式下 FMC 外设时钟使能
  [8] FLITFLPEN — CSleep 模式下 FLITF 时钟使能
  [5] JPGDECLPEN — CSleep 模式下 JPGDEC 时钟使能
  [4] DMA2DLPEN — CSleep 模式下 DMA2D 时钟使能
  [0] MDMALPEN — CSleep 模式下 MDMA 时钟使能
0x160 C1_AHB1LPENR — RCC AHB1 睡眠时钟寄存器
  [28] USB2ULPILPEN — CSleep 模式下 USB_PHY2 时钟使能
  [27] USB2OTGLPEN — CSleep 模式下 USB2OTG 外设时钟使能
  [26] USB1ULPILPEN — CSleep 模式下 USB_PHY1 时钟使能
  [25] USB1OTGLPEN — CSleep 模式下 USB1OTG 外设时钟使能
  [17] ETH1RXLPEN — CSleep 模式下以太网接收时钟使能
  [16] ETH1TXLPEN — CSleep 模式下以太网发送时钟使能
  [15] ETH1MACLPEN — CSleep 模式下以太网 MAC 总线接口时钟使能
  [5] ADC12LPEN — CSleep 模式下 ADC1/2 外设时钟使能
  [1] DMA2LPEN — CSleep 模式下 DMA2 时钟使能
  [0] DMA1LPEN — CSleep 模式下 DMA1 时钟使能
0x164 C1_AHB2LPENR — RCC AHB2 睡眠时钟寄存器
  fields as AHB2LPENR
0x168 C1_AHB4LPENR — RCC AHB4 睡眠时钟寄存器
  fields as AHB4LPENR
0x16C C1_APB3LPENR — RCC APB3 睡眠时钟寄存器
  fields as APB3LPENR
0x170 C1_APB1LLPENR — RCC APB1 低睡眠时钟寄存器
  fields as APB1LLPENR
0x174 C1_APB1HLPENR — RCC APB1 高睡眠时钟寄存器
  fields as APB1HLPENR
0x178 C1_APB2LPENR — RCC APB2 睡眠时钟寄存器
  fields as APB2LPENR
0x17C C1_APB4LPENR — RCC APB4 睡眠时钟寄存器
  fields as APB4LPENR
